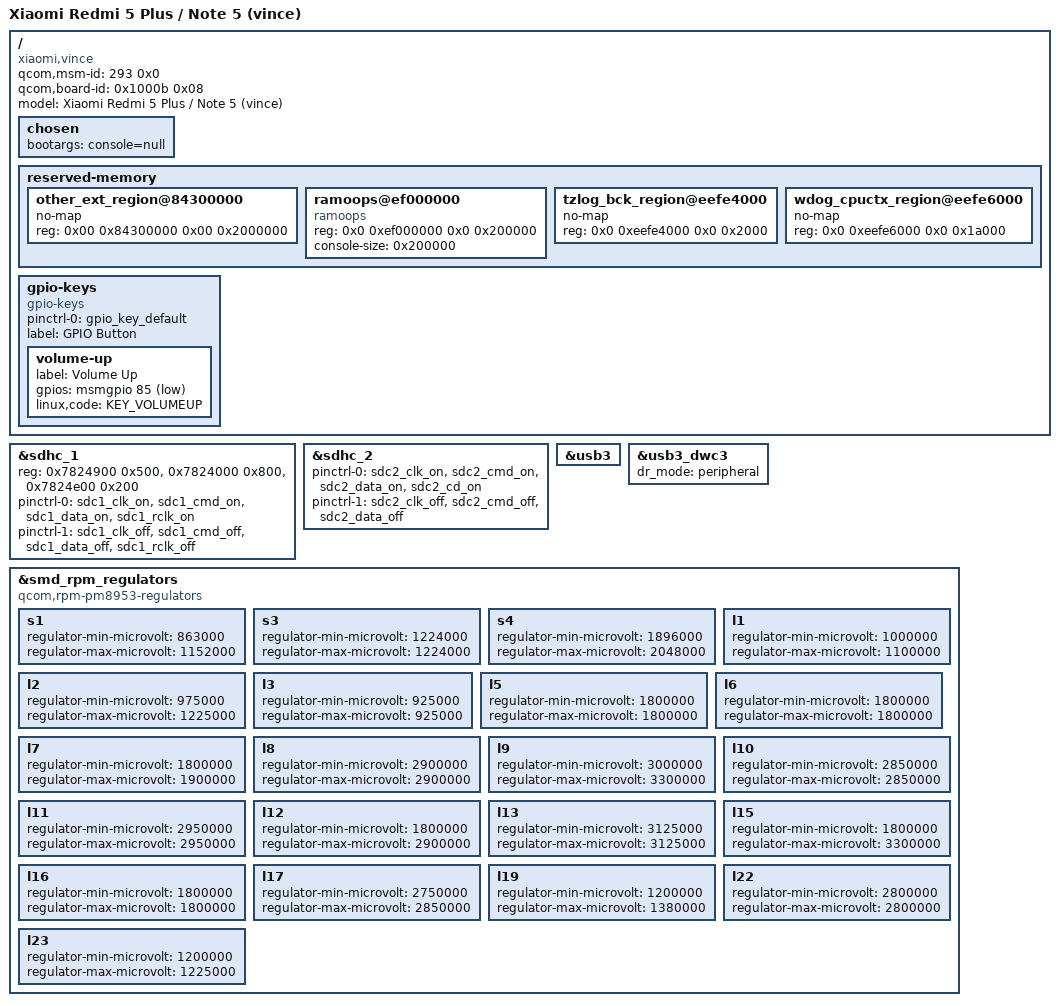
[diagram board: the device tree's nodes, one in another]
// SPDX-License-Identifier: GPL-2.0-only

/dts-v1/;

#include "msm8953.dtsi"
#include "pm8953.dtsi"
#include "pmi8950.dtsi"
#include <dt-bindings/gpio/gpio.h>

/ {
	qcom,msm-id = <293 0x0>;
	qcom,board-id= <0x1000b 0x08>;

	model = "Xiaomi Redmi 5 Plus / Note 5 (vince)";
	compatible = "xiaomi,vince", "qcom,msm8953";

	chosen {
		bootargs = "console=null";
	};

	reserved-memory {
		/delete-node/ other_ext_region@85b00000;

		other_ext_region@84300000 {
			no-map;
			reg = <0x00 0x84300000 0x00 0x2000000>;
		};

		ramoops@ef000000 {
			compatible = "ramoops";
			reg = <0x0 0xef000000 0x0 0x200000>;
			console-size = <0x200000>;
		};

		tzlog_bck_region@eefe4000 {
			no-map;
			reg = <0x0 0xeefe4000 0x0 0x2000>;
		};

		wdog_cpuctx_region@eefe6000 {
			no-map;
			reg = <0x0 0xeefe6000 0x0 0x1a000>;
		};
	};

	gpio-keys {
		compatible = "gpio-keys";

		pinctrl-names = "default";
		pinctrl-0 = <&gpio_key_default>;

		label = "GPIO Button";

		volume-up {
			label = "Volume Up";
			gpios = <&msmgpio 85 GPIO_ACTIVE_LOW>;
			linux,code = <KEY_VOLUMEUP>;
		};
	};
};

&sdhc_1 {
	status = "okay";

	reg = <0x7824900 0x500>, <0x7824000 0x800>, <0x7824e00 0x200>;
	reg-names = "hc_mem", "core_mem", "cmdq_mem";

	pinctrl-names = "active", "sleep";
	pinctrl-0 = <&sdc1_clk_on &sdc1_cmd_on &sdc1_data_on  &sdc1_rclk_on>;
	pinctrl-1 = <&sdc1_clk_off &sdc1_cmd_off &sdc1_data_off &sdc1_rclk_off>;
};

/* Need to be tested */
&sdhc_2 {
	status = "okay";

	pinctrl-names = "active", "sleep";
	pinctrl-0 = <&sdc2_clk_on &sdc2_cmd_on &sdc2_data_on  &sdc2_cd_on>;
	pinctrl-1 = <&sdc2_clk_off &sdc2_cmd_off &sdc2_data_off>;
};

&usb3 {
	status = "okay";
};

&usb3_dwc3 {
	dr_mode = "peripheral";
};

&smd_rpm_regulators {
	compatible = "qcom,rpm-pm8953-regulators";

	s1 {
		regulator-min-microvolt = <863000>;
		regulator-max-microvolt = <1152000>;
	};
	s3 {
		regulator-min-microvolt = <1224000>;
		regulator-max-microvolt = <1224000>;
	};
	s4 {
		regulator-min-microvolt = <1896000>;
		regulator-max-microvolt = <2048000>;
	};
	l1 {
		regulator-min-microvolt = <1000000>;
		regulator-max-microvolt = <1100000>;
	};
	l2 {
		regulator-min-microvolt = <975000>;
		regulator-max-microvolt = <1225000>;
	};
	l3 {
		regulator-min-microvolt = <925000>;
		regulator-max-microvolt = <925000>;
	};
	l5 {
		regulator-min-microvolt = <1800000>;
		regulator-max-microvolt = <1800000>;
	};
	l6 {
		regulator-min-microvolt = <1800000>;
		regulator-max-microvolt = <1800000>;
	};
	l7 {
		regulator-min-microvolt = <1800000>;
		regulator-max-microvolt = <1900000>;
        };
	l8 {
		regulator-min-microvolt = <2900000>;
		regulator-max-microvolt = <2900000>;
	};
	l9 {
		regulator-min-microvolt = <3000000>;
		regulator-max-microvolt = <3300000>;
	};
	l10 {
		regulator-min-microvolt = <2850000>;
		regulator-max-microvolt = <2850000>;
	};
	l11 {
		regulator-min-microvolt = <2950000>;
		regulator-max-microvolt = <2950000>;
	};
	l12 {
		regulator-min-microvolt = <1800000>;
		regulator-max-microvolt = <2900000>;
	};
	l13 {
		regulator-min-microvolt = <3125000>;
		regulator-max-microvolt = <3125000>;
	};
	l15 {
		regulator-min-microvolt = <1800000>;
		regulator-max-microvolt = <3300000>;
	};
	l16 {
		regulator-min-microvolt = <1800000>;
		regulator-max-microvolt = <1800000>;
	};
	l17 {
		regulator-min-microvolt = <2750000>;
		regulator-max-microvolt = <2850000>;
	};
	l19 {
		regulator-min-microvolt = <1200000>;
		regulator-max-microvolt = <1380000>;
	};
	l22 {
		regulator-min-microvolt = <2800000>;
		regulator-max-microvolt = <2800000>;
	};
	l23 {
		regulator-min-microvolt = <1200000>;
		regulator-max-microvolt = <1225000>;
	};
};
